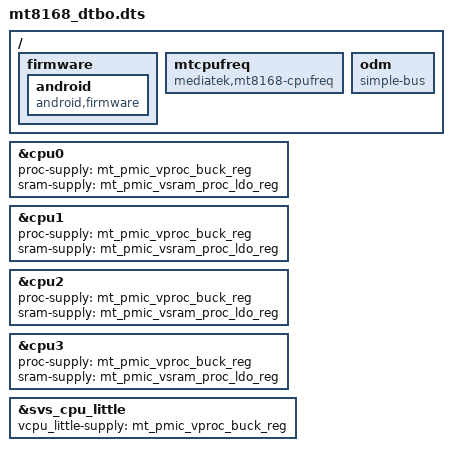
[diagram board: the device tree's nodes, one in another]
/*
 * Mediatek's MT8168 SoC base device tree for device tree overlay
 * Copyright (c) 2017 MediaTek Inc.
 *
 * This program is free software; you can redistribute it and/or modify
 * it under the terms of the GNU General Public License version 2 as
 * published by the Free Software Foundation.
 *
 * This program is distributed in the hope that it will be useful,
 * MERCHANTABILITY or FITNESS FOR A PARTICULAR PURPOSE.  See the
 * GNU General Public License for more details.
 */

/dts-v1/;

#include "mt8168.dtsi"
#include "mt6357.dtsi"

/ {
	firmware: firmware {
		android: android {
			compatible = "android,firmware";
		};
	};

	mtcpufreq {
		compatible = "mediatek,mt8168-cpufreq";
	};

	odm: odm {
		compatible = "simple-bus";
		/* reserved for overlay by odm */
	};
};

&cpu0 {
	proc-supply = <&mt_pmic_vproc_buck_reg>;
	sram-supply = <&mt_pmic_vsram_proc_ldo_reg>;
};

&cpu1 {
	proc-supply = <&mt_pmic_vproc_buck_reg>;
	sram-supply = <&mt_pmic_vsram_proc_ldo_reg>;
};

&cpu2 {
	proc-supply = <&mt_pmic_vproc_buck_reg>;
	sram-supply = <&mt_pmic_vsram_proc_ldo_reg>;
};

&cpu3 {
	proc-supply = <&mt_pmic_vproc_buck_reg>;
	sram-supply = <&mt_pmic_vsram_proc_ldo_reg>;
};

&svs_cpu_little {
	vcpu_little-supply = <&mt_pmic_vproc_buck_reg>;
};
